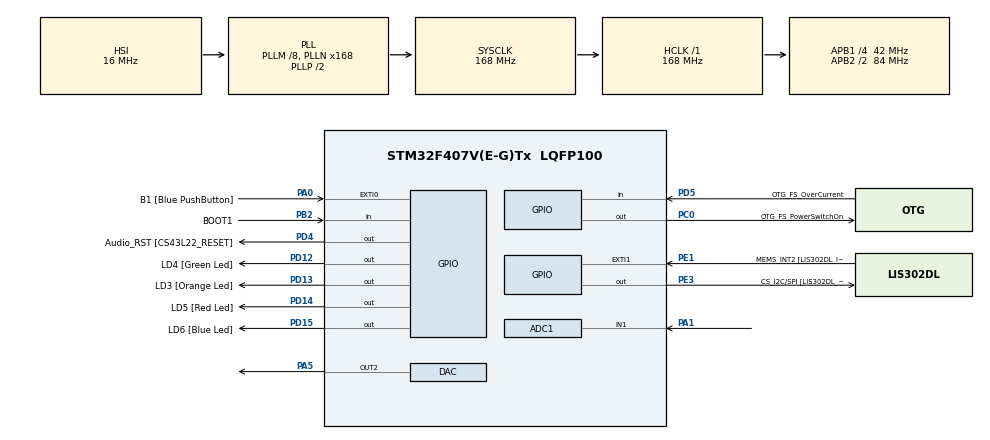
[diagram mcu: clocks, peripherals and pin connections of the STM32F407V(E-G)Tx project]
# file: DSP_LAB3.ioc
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ADC1.Channel-0\#ChannelRegularConversion=ADC_CHANNEL_1
ADC1.DMAContinuousRequests=ENABLE
ADC1.ExternalTrigConv=ADC_EXTERNALTRIGCONV_T3_TRGO
ADC1.NbrOfConversionFlag=1
ADC1.Rank-0\#ChannelRegularConversion=1
ADC1.SamplingTime-0\#ChannelRegularConversion=ADC_SAMPLETIME_3CYCLES
ADC1.master=1
DAC.DAC_Trigger2=DAC_TRIGGER_NONE
Dma.ADC1.0.Direction=DMA_PERIPH_TO_MEMORY
Dma.ADC1.0.FIFOMode=DMA_FIFOMODE_DISABLE
Dma.ADC1.0.Instance=DMA2_Stream0
Dma.ADC1.0.MemDataAlignment=DMA_MDATAALIGN_HALFWORD
Dma.ADC1.0.MemInc=DMA_MINC_ENABLE
Dma.ADC1.0.Mode=DMA_CIRCULAR
Dma.ADC1.0.PeriphDataAlignment=DMA_PDATAALIGN_HALFWORD
Dma.ADC1.0.PeriphInc=DMA_PINC_DISABLE
Dma.ADC1.0.Priority=DMA_PRIORITY_LOW
Dma.Request0=ADC1
Mcu.Family=STM32F4
Mcu.Name=STM32F407V(E-G)Tx
Mcu.Package=LQFP100
NVIC.DMA2_Stream0_IRQn=true\:0\:0\:false\:false\:true\:false\:true\:true
NVIC.PriorityGroup=NVIC_PRIORITYGROUP_0
PA0-WKUP.GPIO_Label=B1 [Blue PushButton]
PA0-WKUP.Signal=GPXTI0
PA1.Signal=ADCx_IN1
PA10.GPIO_Label=OTG_FS_ID
PA10.GPIO_Mode=GPIO_MODE_AF_PP
PA10.GPIO_PuPd=GPIO_NOPULL
PA10.GPIO_Speed=GPIO_SPEED_FREQ_LOW
PA10.Signal=USB_OTG_FS_ID
PA11.GPIO_Label=OTG_FS_DM
PA11.GPIO_Mode=GPIO_MODE_AF_PP
PA11.GPIO_PuPd=GPIO_NOPULL
PA11.GPIO_Speed=GPIO_SPEED_FREQ_LOW
PA11.Signal=USB_OTG_FS_DM
PA12.GPIO_Label=OTG_FS_DP
PA12.GPIO_Mode=GPIO_MODE_AF_PP
PA12.GPIO_PuPd=GPIO_NOPULL
PA12.GPIO_Speed=GPIO_SPEED_FREQ_LOW
PA12.Signal=USB_OTG_FS_DP
PA13.GPIO_Label=SWDIO
PA13.Signal=SYS_JTMS-SWDIO
PA14.GPIO_Label=SWCLK
PA14.Signal=SYS_JTCK-SWCLK
PA5.Signal=COMP_DAC2_group
PA6.GPIO_Label=SPI1_MISO [LIS302DL_SDO]
PA6.GPIO_Mode=GPIO_MODE_AF_PP
PA6.GPIO_PuPd=GPIO_NOPULL
PA6.GPIO_Speed=GPIO_SPEED_FREQ_LOW
PA6.Signal=SPI1_MISO
PA7.GPIO_Label=SPI1_MOSI [LIS302DL_SDA/SDI/SDO]
PA7.GPIO_Mode=GPIO_MODE_AF_PP
PA7.GPIO_PuPd=GPIO_NOPULL
PA7.GPIO_Speed=GPIO_SPEED_FREQ_LOW
PA7.Signal=SPI1_MOSI
PA9.GPIO_Label=VBUS_FS
PA9.GPIO_Mode=GPIO_MODE_INPUT
PA9.GPIO_PuPd=GPIO_NOPULL
PA9.Signal=USB_OTG_FS_VBUS
PB10.GPIO_Label=CLK_IN [MP45DT02_CLK]
PB10.GPIO_Mode=GPIO_MODE_AF_PP
PB10.GPIO_PuPd=GPIO_NOPULL
PB10.GPIO_Speed=GPIO_SPEED_FREQ_LOW
PB10.Signal=I2S2_CK
PB2.GPIO_Label=BOOT1
PB2.GPIO_Mode=GPIO_MODE_INPUT
PB2.GPIO_PuPd=GPIO_NOPULL
PB2.Signal=GPIO_Input
PB3.GPIO_Label=SWO
PB3.Signal=SYS_JTDO-SWO
PB6.GPIO_Label=Audio_SCL [CS43L22_SCL]
PB6.GPIO_Mode=GPIO_MODE_AF_OD
PB6.GPIO_PuPd=GPIO_NOPULL
PB6.GPIO_Speed=GPIO_SPEED_FREQ_LOW
PB6.Signal=I2C1_SCL
PB9.GPIO_Label=Audio_SDA [CS43L22_SDA]
PB9.GPIO_Mode=GPIO_MODE_AF_OD
PB9.GPIO_PuPd=GPIO_NOPULL
PB9.GPIO_Speed=GPIO_SPEED_FREQ_LOW
PB9.Signal=I2C1_SDA
PC0.GPIO_Label=OTG_FS_PowerSwitchOn
PC0.GPIO_PuPd=GPIO_NOPULL
PC0.GPIO_Speed=GPIO_SPEED_FREQ_LOW
PC0.PinState=GPIO_PIN_SET
PC0.Signal=GPIO_Output
PC10.GPIO_Label=I2S3_SCK [CS43L22_SCLK]
PC10.GPIO_Mode=GPIO_MODE_AF_PP
PC10.GPIO_PuPd=GPIO_NOPULL
PC10.GPIO_Speed=GPIO_SPEED_FREQ_LOW
PC10.Signal=I2S3_CK
PC12.GPIO_Label=I2S3_SD [CS43L22_SDIN]
PC12.GPIO_Mode=GPIO_MODE_AF_PP
PC12.GPIO_PuPd=GPIO_NOPULL
PC12.GPIO_Speed=GPIO_SPEED_FREQ_LOW
PC12.Signal=I2S3_SD
PC14-OSC32_IN.GPIO_Label=PC14-OSC32_IN
PC14-OSC32_IN.Signal=RCC_OSC32_IN
PC15-OSC32_OUT.GPIO_Label=PC15-OSC32_OUT
PC15-OSC32_OUT.Signal=RCC_OSC32_OUT
PC3.GPIO_Label=PDM_OUT [MP45DT02_DOUT]
PC3.GPIO_Mode=GPIO_MODE_AF_PP
PC3.GPIO_PuPd=GPIO_NOPULL
PC3.GPIO_Speed=GPIO_SPEED_FREQ_LOW
PC3.Signal=I2S2_SD
PC7.GPIO_Label=I2S3_MCK [CS43L22_MCLK]
PC7.GPIO_Mode=GPIO_MODE_AF_PP
PC7.GPIO_PuPd=GPIO_NOPULL
PC7.GPIO_Speed=GPIO_SPEED_FREQ_LOW
PC7.Signal=I2S3_MCK
PD12.GPIO_Label=LD4 [Green Led]
PD12.GPIO_PuPd=GPIO_NOPULL
PD12.GPIO_Speed=GPIO_SPEED_FREQ_LOW
PD12.Signal=GPIO_Output
PD13.GPIO_Label=LD3 [Orange Led]
PD13.GPIO_PuPd=GPIO_NOPULL
PD13.GPIO_Speed=GPIO_SPEED_FREQ_LOW
PD13.Signal=GPIO_Output
PD14.GPIO_Label=LD5 [Red Led]
PD14.GPIO_PuPd=GPIO_NOPULL
PD14.GPIO_Speed=GPIO_SPEED_FREQ_LOW
PD14.Signal=GPIO_Output
PD15.GPIO_Label=LD6 [Blue Led]
PD15.GPIO_PuPd=GPIO_NOPULL
PD15.GPIO_Speed=GPIO_SPEED_FREQ_LOW
PD15.Signal=GPIO_Output
PD4.GPIO_Label=Audio_RST [CS43L22_RESET]
PD4.GPIO_PuPd=GPIO_NOPULL
PD4.GPIO_Speed=GPIO_SPEED_FREQ_LOW
PD4.Signal=GPIO_Output
PD5.GPIO_Label=OTG_FS_OverCurrent
PD5.GPIO_Mode=GPIO_MODE_INPUT
PD5.GPIO_PuPd=GPIO_NOPULL
PD5.Signal=GPIO_Input
PE1.GPIO_Label=MEMS_INT2 [LIS302DL_INT2]
PE1.GPIO_ModeDefaultEXTI=GPIO_MODE_EVT_RISING
PE1.GPIO_PuPd=GPIO_NOPULL
PE1.Signal=GPXTI1
PE3.GPIO_Label=CS_I2C/SPI [LIS302DL_CS_I2C/SPI]
PE3.GPIO_PuPd=GPIO_NOPULL
PE3.GPIO_Speed=GPIO_SPEED_FREQ_LOW
PE3.Signal=GPIO_Output
PH0-OSC_IN.GPIO_Label=PH0-OSC_IN
PH0-OSC_IN.Signal=RCC_OSC_IN
PH1-OSC_OUT.GPIO_Label=PH1-OSC_OUT
PH1-OSC_OUT.Signal=RCC_OSC_OUT
ProjectManager.HeapSize=0x200
ProjectManager.StackSize=0x400
ProjectManager.TargetToolchain=STM32CubeIDE
RCC.48MHZClocksFreq_Value=48000000
RCC.AHBFreq_Value=168000000
RCC.APB1CLKDivider=RCC_HCLK_DIV4
RCC.APB1Freq_Value=42000000
RCC.APB1TimFreq_Value=84000000
RCC.APB2CLKDivider=RCC_HCLK_DIV2
RCC.APB2Freq_Value=84000000
RCC.APB2TimFreq_Value=168000000
RCC.CortexFreq_Value=168000000
RCC.HCLKFreq_Value=168000000
RCC.HSE_VALUE=8000000
RCC.HSI_VALUE=16000000
RCC.LSE_VALUE=32768
RCC.PLLM=8
RCC.PLLN=168
RCC.PLLQ=7
RCC.SYSCLKFreq_VALUE=168000000
RCC.SYSCLKSource=RCC_SYSCLKSOURCE_PLLCLK
RCC.VCOOutputFreq_Value=336000000
SH.ADCx_IN1.0=ADC1_IN1,IN1
SH.COMP_DAC2_group.0=DAC_OUT2,DAC_OUT2
TIM3.Period=4
TIM3.Prescaler=20
TIM3.TIM_MasterOutputTrigger=TIM_TRGO_UPDATE
VP_TIM3_VS_ClockSourceINT.Mode=Internal
board=STM32F407G-DISC1

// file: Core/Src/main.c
/* USER CODE BEGIN Header */
/**
  ******************************************************************************
  * @file           : main.c
  * @brief          : Main program body
  ******************************************************************************
  * @attention
  *
  * Copyright (c) 2022 STMicroelectronics.
  * All rights reserved.
  *
  * This software is licensed under terms that can be found in the LICENSE file
  * in the root directory of this software component.
  * If no LICENSE file comes with this software, it is provided AS-IS.
  *
  ******************************************************************************
  */
/* USER CODE END Header */
#include "main.h"
#include "adc.h"
#include "dac.h"
#include "dma.h"
#include "tim.h"
#include "gpio.h"

void SystemClock_Config(void);

/* USER CODE BEGIN 0 */
#define BUFFER_SIZE 16
#define SIZE_AFTER_OVERS 300
int16_t Buffer[BUFFER_SIZE];

void HAL_ADC_ConvCpltCallback(ADC_HandleTypeDef* hadc)
{
	int32_t sum = 0;
	for(int overs_index = 0 ; overs_index<BUFFER_SIZE ; overs_index++)
	{
		sum += Buffer[overs_index];
	}
	HAL_DAC_SetValue(&hdac, DAC_CHANNEL_2, DAC_ALIGN_12B_L, sum);
}

/* USER CODE END 0 */

/**
  * @brief  The application entry point.
  * @retval int
  */s
int main(void)
{

  /* MCU Configuration--------------------------------------------------------*/

  /* Reset of all peripherals, Initializes the Flash interface and the Systick. */
  HAL_Init();

  /* Configure the system clock */
  SystemClock_Config();

  /* Initialize all configured peripherals */
  MX_GPIO_Init();
  MX_DMA_Init();
  MX_DAC_Init();
  MX_ADC1_Init();
  MX_TIM3_Init();
  /* USER CODE BEGIN 2 */
  for(int i = 0 ; i<BUFFER_SIZE ; i++)
  {
	  Buffer[i] = 0;
  }

  HAL_ADC_Start_DMA(&hadc1, (uint32_t*)Buffer, BUFFER_SIZE);
  HAL_TIM_Base_Start(&htim3) ;
  HAL_DAC_Start(&hdac, DAC_CHANNEL_2);
  /* USER CODE END 2 */

  /* Infinite loop */
  while (1)
  {

  }
}

void SystemClock_Config(void)
{
  RCC_OscInitTypeDef RCC_OscInitStruct = {0};
  RCC_ClkInitTypeDef RCC_ClkInitStruct = {0};

  /** Configure the main internal regulator output voltage
  */
  __HAL_RCC_PWR_CLK_ENABLE();
  __HAL_PWR_VOLTAGESCALING_CONFIG(PWR_REGULATOR_VOLTAGE_SCALE1);

  /** Initializes the RCC Oscillators according to the specified parameters
  * in the RCC_OscInitTypeDef structure.
  */
  RCC_OscInitStruct.OscillatorType = RCC_OSCILLATORTYPE_HSI;
  RCC_OscInitStruct.HSIState = RCC_HSI_ON;
  RCC_OscInitStruct.HSICalibrationValue = RCC_HSICALIBRATION_DEFAULT;
  RCC_OscInitStruct.PLL.PLLState = RCC_PLL_ON;
  RCC_OscInitStruct.PLL.PLLSource = RCC_PLLSOURCE_HSI;
  RCC_OscInitStruct.PLL.PLLM = 8;
  RCC_OscInitStruct.PLL.PLLN = 168;
  RCC_OscInitStruct.PLL.PLLP = RCC_PLLP_DIV2;
  RCC_OscInitStruct.PLL.PLLQ = 7;
  if (HAL_RCC_OscConfig(&RCC_OscInitStruct) != HAL_OK)
  {
    Error_Handler();
  }

  /** Initializes the CPU, AHB and APB buses clocks
  */
  RCC_ClkInitStruct.ClockType = RCC_CLOCKTYPE_HCLK|RCC_CLOCKTYPE_SYSCLK
                              |RCC_CLOCKTYPE_PCLK1|RCC_CLOCKTYPE_PCLK2;
  RCC_ClkInitStruct.SYSCLKSource = RCC_SYSCLKSOURCE_PLLCLK;
  RCC_ClkInitStruct.AHBCLKDivider = RCC_SYSCLK_DIV1;
  RCC_ClkInitStruct.APB1CLKDivider = RCC_HCLK_DIV4;
  RCC_ClkInitStruct.APB2CLKDivider = RCC_HCLK_DIV2;

  if (HAL_RCC_ClockConfig(&RCC_ClkInitStruct, FLASH_LATENCY_5) != HAL_OK)
  {
    Error_Handler();
  }
}

void Error_Handler(void)
{
  __disable_irq();
  while (1)
  {
  }
}
